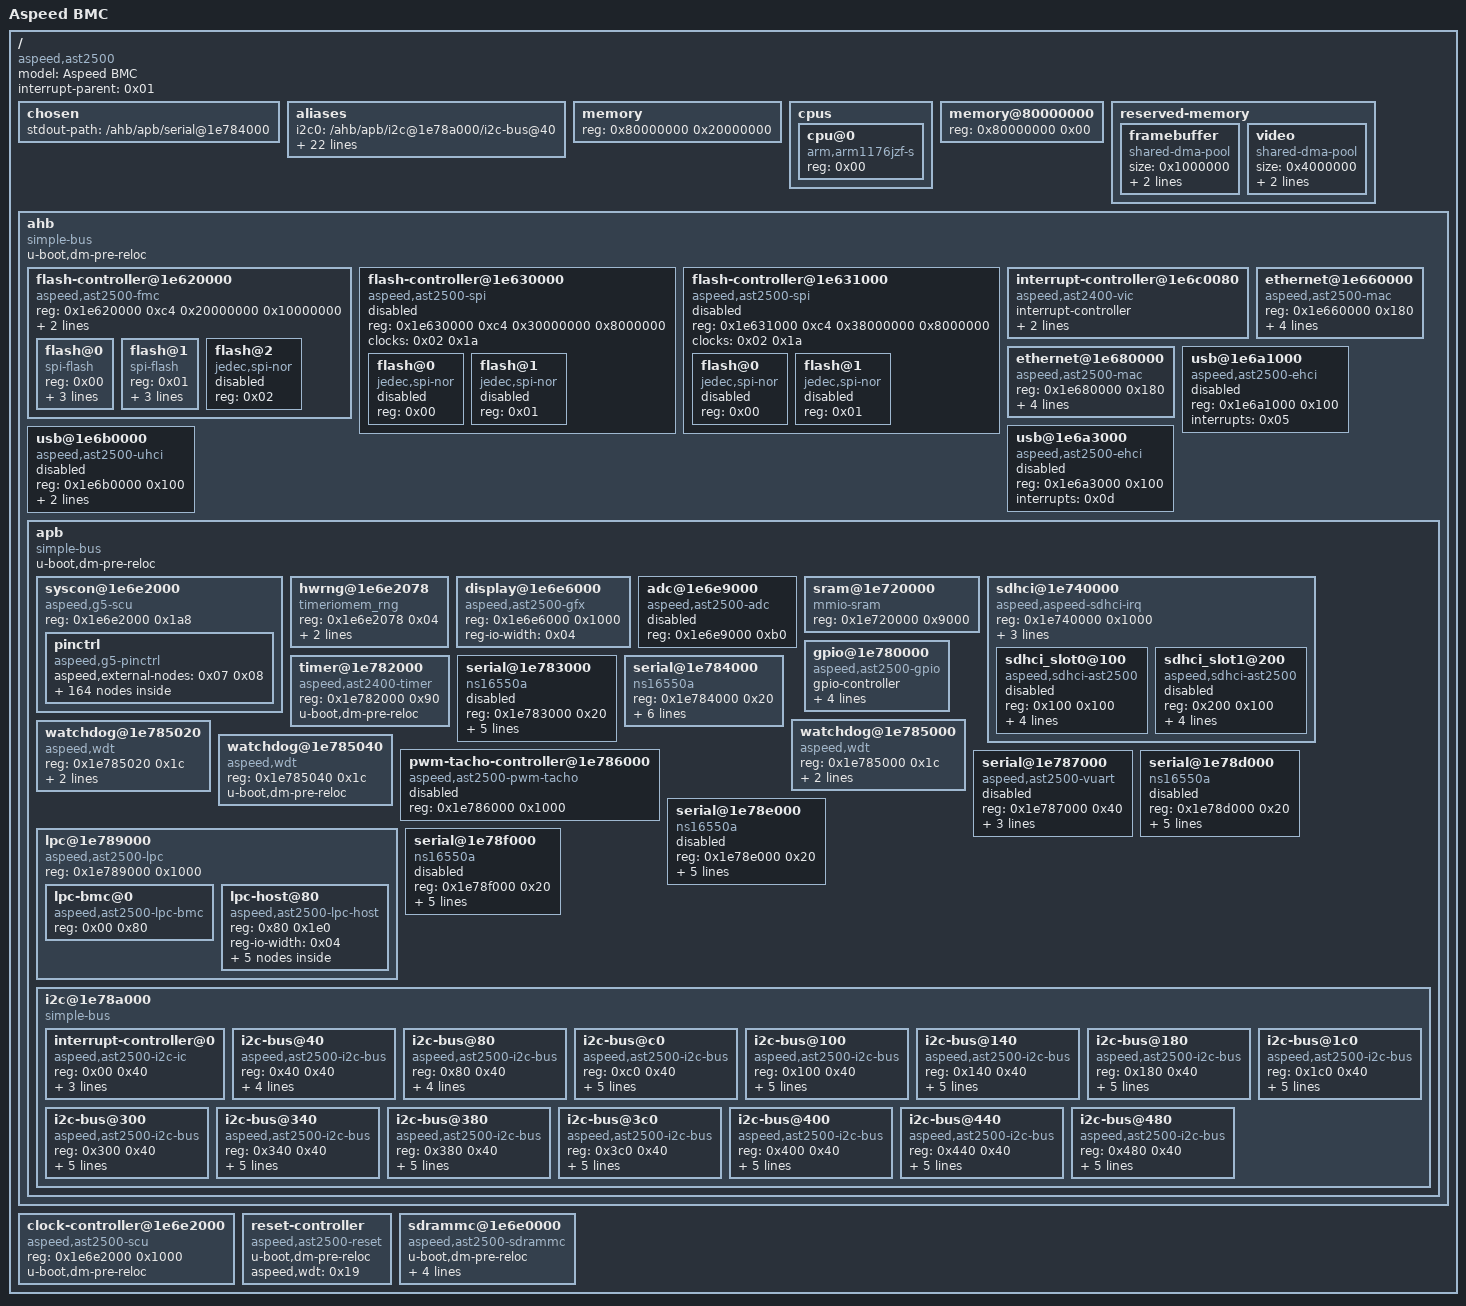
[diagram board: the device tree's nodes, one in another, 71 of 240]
/dts-v1/;

/ {
	#address-cells = <0x01>;
	#size-cells = <0x01>;
	model = "Aspeed BMC";
	compatible = "aspeed,ast2500";
	interrupt-parent = <0x01>;

	chosen {
		stdout-path = "/ahb/apb/serial@1e784000";
	};

	aliases {
		i2c0 = "/ahb/apb/i2c@1e78a000/i2c-bus@40";
		i2c1 = "/ahb/apb/i2c@1e78a000/i2c-bus@80";
		i2c2 = "/ahb/apb/i2c@1e78a000/i2c-bus@c0";
		i2c3 = "/ahb/apb/i2c@1e78a000/i2c-bus@100";
		i2c4 = "/ahb/apb/i2c@1e78a000/i2c-bus@140";
		i2c5 = "/ahb/apb/i2c@1e78a000/i2c-bus@180";
		i2c6 = "/ahb/apb/i2c@1e78a000/i2c-bus@1c0";
		i2c7 = "/ahb/apb/i2c@1e78a000/i2c-bus@300";
		i2c8 = "/ahb/apb/i2c@1e78a000/i2c-bus@340";
		i2c9 = "/ahb/apb/i2c@1e78a000/i2c-bus@380";
		i2c10 = "/ahb/apb/i2c@1e78a000/i2c-bus@3c0";
		i2c11 = "/ahb/apb/i2c@1e78a000/i2c-bus@400";
		i2c12 = "/ahb/apb/i2c@1e78a000/i2c-bus@440";
		i2c13 = "/ahb/apb/i2c@1e78a000/i2c-bus@480";
		serial0 = "/ahb/apb/serial@1e783000";
		serial1 = "/ahb/apb/serial@1e78d000";
		serial2 = "/ahb/apb/serial@1e78e000";
		serial3 = "/ahb/apb/serial@1e78f000";
		serial4 = "/ahb/apb/serial@1e784000";
		serial5 = "/ahb/apb/serial@1e787000";
		spi0 = "/ahb/flash-controller@1e620000";
		ethernet0 = "/ahb/ethernet@1e660000";
		ethernet1 = "/ahb/ethernet@1e680000";
	};

	memory {
		device_type = "memory";
		reg = <0x80000000 0x20000000>;
	};

	cpus {
		#address-cells = <0x01>;
		#size-cells = <0x00>;

		cpu@0 {
			compatible = "arm,arm1176jzf-s";
			device_type = "cpu";
			reg = <0x00>;
		};
	};

	memory@80000000 {
		device_type = "memory";
		reg = <0x80000000 0x00>;
	};

	reserved-memory {
		#address-cells = <0x01>;
		#size-cells = <0x01>;
		ranges;

		framebuffer {
			size = <0x1000000>;
			alignment = <0x1000000>;
			compatible = "shared-dma-pool";
			reusable;
		};

		video {
			size = <0x4000000>;
			alignment = <0x1000000>;
			compatible = "shared-dma-pool";
			no-map;
		};
	};

	ahb {
		compatible = "simple-bus";
		#address-cells = <0x01>;
		#size-cells = <0x01>;
		ranges;
		u-boot,dm-pre-reloc;

		flash-controller@1e620000 {
			reg = <0x1e620000 0xc4 0x20000000 0x10000000>;
			#address-cells = <0x01>;
			#size-cells = <0x00>;
			compatible = "aspeed,ast2500-fmc";
			status = "okay";
			interrupts = <0x13>;
			clocks = <0x02 0x1a>;

			flash@0 {
				reg = <0x00>;
				compatible = "spi-flash", "sst,w25q256";
				status = "okay";
				spi-max-frequency = <0x2faf080>;
				spi-tx-bus-width = <0x02>;
				spi-rx-bus-width = <0x02>;
			};

			flash@1 {
				reg = <0x01>;
				compatible = "spi-flash", "sst,w25q256";
				status = "okay";
				spi-max-frequency = <0x2faf080>;
				spi-tx-bus-width = <0x02>;
				spi-rx-bus-width = <0x02>;
			};

			flash@2 {
				reg = <0x02>;
				compatible = "jedec,spi-nor";
				status = "disabled";
			};
		};

		flash-controller@1e630000 {
			reg = <0x1e630000 0xc4 0x30000000 0x8000000>;
			#address-cells = <0x01>;
			#size-cells = <0x00>;
			compatible = "aspeed,ast2500-spi";
			clocks = <0x02 0x1a>;
			status = "disabled";

			flash@0 {
				reg = <0x00>;
				compatible = "jedec,spi-nor";
				status = "disabled";
			};

			flash@1 {
				reg = <0x01>;
				compatible = "jedec,spi-nor";
				status = "disabled";
			};
		};

		flash-controller@1e631000 {
			reg = <0x1e631000 0xc4 0x38000000 0x8000000>;
			#address-cells = <0x01>;
			#size-cells = <0x00>;
			compatible = "aspeed,ast2500-spi";
			clocks = <0x02 0x1a>;
			status = "disabled";

			flash@0 {
				reg = <0x00>;
				compatible = "jedec,spi-nor";
				status = "disabled";
			};

			flash@1 {
				reg = <0x01>;
				compatible = "jedec,spi-nor";
				status = "disabled";
			};
		};

		interrupt-controller@1e6c0080 {
			compatible = "aspeed,ast2400-vic";
			interrupt-controller;
			#interrupt-cells = <0x01>;
			valid-sources = <0xfefff7ff 0x807ffff>;
			reg = <0x1e6c0080 0x80>;
			phandle = <0x01>;
		};

		ethernet@1e660000 {
			compatible = "aspeed,ast2500-mac", "faraday,ftgmac100";
			reg = <0x1e660000 0x180>;
			interrupts = <0x02>;
			clocks = <0x02 0x11 0x02 0x26>;
			status = "okay";
			phy-mode = "rgmii";
			pinctrl-names = "default";
			pinctrl-0 = <0x03 0x04>;
		};

		ethernet@1e680000 {
			compatible = "aspeed,ast2500-mac", "faraday,ftgmac100";
			reg = <0x1e680000 0x180>;
			interrupts = <0x03>;
			clocks = <0x02 0x12 0x02 0x26>;
			status = "okay";
			phy-mode = "rgmii";
			pinctrl-names = "default";
			pinctrl-0 = <0x05 0x06>;
		};

		usb@1e6a1000 {
			compatible = "aspeed,ast2500-ehci", "generic-ehci";
			reg = <0x1e6a1000 0x100>;
			interrupts = <0x05>;
			status = "disabled";
		};

		usb@1e6a3000 {
			compatible = "aspeed,ast2500-ehci", "generic-ehci";
			reg = <0x1e6a3000 0x100>;
			interrupts = <0x0d>;
			status = "disabled";
		};

		usb@1e6b0000 {
			compatible = "aspeed,ast2500-uhci", "generic-uhci";
			reg = <0x1e6b0000 0x100>;
			interrupts = <0x0e>;
			#ports = <0x02>;
			status = "disabled";
		};

		apb {
			compatible = "simple-bus";
			#address-cells = <0x01>;
			#size-cells = <0x01>;
			ranges;
			u-boot,dm-pre-reloc;

			syscon@1e6e2000 {
				compatible = "aspeed,g5-scu", "syscon", "simple-mfd";
				reg = <0x1e6e2000 0x1a8>;
				#clock-cells = <0x01>;
				#reset-cells = <0x01>;

				pinctrl {
					compatible = "aspeed,g5-pinctrl";
					aspeed,external-nodes = <0x07 0x08>;
					phandle = <0x0a>;

					acpi_default {
						function = "ACPI";
						groups = "ACPI";
					};

					adc0_default {
						function = "ADC0";
						groups = "ADC0";
					};

					adc1_default {
						function = "ADC1";
						groups = "ADC1";
					};

					adc10_default {
						function = "ADC10";
						groups = "ADC10";
					};

					adc11_default {
						function = "ADC11";
						groups = "ADC11";
					};

					adc12_default {
						function = "ADC12";
						groups = "ADC12";
					};

					adc13_default {
						function = "ADC13";
						groups = "ADC13";
					};

					adc14_default {
						function = "ADC14";
						groups = "ADC14";
					};

					adc15_default {
						function = "ADC15";
						groups = "ADC15";
					};

					adc2_default {
						function = "ADC2";
						groups = "ADC2";
					};

					adc3_default {
						function = "ADC3";
						groups = "ADC3";
					};

					adc4_default {
						function = "ADC4";
						groups = "ADC4";
					};

					adc5_default {
						function = "ADC5";
						groups = "ADC5";
					};

					adc6_default {
						function = "ADC6";
						groups = "ADC6";
					};

					adc7_default {
						function = "ADC7";
						groups = "ADC7";
					};

					adc8_default {
						function = "ADC8";
						groups = "ADC8";
					};

					adc9_default {
						function = "ADC9";
						groups = "ADC9";
					};

					bmcint_default {
						function = "BMCINT";
						groups = "BMCINT";
					};

					ddcclk_default {
						function = "DDCCLK";
						groups = "DDCCLK";
					};

					ddcdat_default {
						function = "DDCDAT";
						groups = "DDCDAT";
					};

					espi_default {
						function = "ESPI";
						groups = "ESPI";
					};

					fwspics1_default {
						function = "FWSPICS1";
						groups = "FWSPICS1";
					};

					fwspics2_default {
						function = "FWSPICS2";
						groups = "FWSPICS2";
					};

					gpid0_default {
						function = "GPID0";
						groups = "GPID0";
					};

					gpid2_default {
						function = "GPID2";
						groups = "GPID2";
					};

					gpid4_default {
						function = "GPID4";
						groups = "GPID4";
					};

					gpid6_default {
						function = "GPID6";
						groups = "GPID6";
					};

					gpie0_default {
						function = "GPIE0";
						groups = "GPIE0";
					};

					gpie2_default {
						function = "GPIE2";
						groups = "GPIE2";
					};

					gpie4_default {
						function = "GPIE4";
						groups = "GPIE4";
					};

					gpie6_default {
						function = "GPIE6";
						groups = "GPIE6";
					};

					i2c10_default {
						function = "I2C10";
						groups = "I2C10";
						phandle = <0x14>;
					};

					i2c11_default {
						function = "I2C11";
						groups = "I2C11";
						phandle = <0x15>;
					};

					i2c12_default {
						function = "I2C12";
						groups = "I2C12";
						phandle = <0x16>;
					};

					i2c13_default {
						function = "I2C13";
						groups = "I2C13";
						phandle = <0x17>;
					};

					i2c14_default {
						function = "I2C14";
						groups = "I2C14";
						phandle = <0x18>;
					};

					i2c3_default {
						function = "I2C3";
						groups = "I2C3";
						phandle = <0x0d>;
					};

					i2c4_default {
						function = "I2C4";
						groups = "I2C4";
						phandle = <0x0e>;
					};

					i2c5_default {
						function = "I2C5";
						groups = "I2C5";
						phandle = <0x0f>;
					};

					i2c6_default {
						function = "I2C6";
						groups = "I2C6";
						phandle = <0x10>;
					};

					i2c7_default {
						function = "I2C7";
						groups = "I2C7";
						phandle = <0x11>;
					};

					i2c8_default {
						function = "I2C8";
						groups = "I2C8";
						phandle = <0x12>;
					};

					i2c9_default {
						function = "I2C9";
						groups = "I2C9";
						phandle = <0x13>;
					};

					lad0_default {
						function = "LAD0";
						groups = "LAD0";
					};

					lad1_default {
						function = "LAD1";
						groups = "LAD1";
					};

					lad2_default {
						function = "LAD2";
						groups = "LAD2";
					};

					lad3_default {
						function = "LAD3";
						groups = "LAD3";
					};

					lclk_default {
						function = "LCLK";
						groups = "LCLK";
					};

					lframe_default {
						function = "LFRAME";
						groups = "LFRAME";
					};

					lpchc_default {
						function = "LPCHC";
						groups = "LPCHC";
					};

					lpcpd_default {
						function = "LPCPD";
						groups = "LPCPD";
					};

					lpcplus_default {
						function = "LPCPLUS";
						groups = "LPCPLUS";
					};

					lpcpme_default {
						function = "LPCPME";
						groups = "LPCPME";
					};

					lpcrst_default {
						function = "LPCRST";
						groups = "LPCRST";
					};

					lpcsmi_default {
						function = "LPCSMI";
						groups = "LPCSMI";
					};

					lsirq_default {
						function = "LSIRQ";
						groups = "LSIRQ";
					};

					mac1link_default {
						function = "MAC1LINK";
						groups = "MAC1LINK";
						phandle = <0x03>;
					};

					mac2link_default {
						function = "MAC2LINK";
						groups = "MAC2LINK";
						phandle = <0x05>;
					};

					mdio1_default {
						function = "MDIO1";
						groups = "MDIO1";
						phandle = <0x04>;
					};

					mdio2_default {
						function = "MDIO2";
						groups = "MDIO2";
						phandle = <0x06>;
					};

					ncts1_default {
						function = "NCTS1";
						groups = "NCTS1";
					};

					ncts2_default {
						function = "NCTS2";
						groups = "NCTS2";
					};

					ncts3_default {
						function = "NCTS3";
						groups = "NCTS3";
					};

					ncts4_default {
						function = "NCTS4";
						groups = "NCTS4";
					};

					ndcd1_default {
						function = "NDCD1";
						groups = "NDCD1";
					};

					ndcd2_default {
						function = "NDCD2";
						groups = "NDCD2";
					};

					ndcd3_default {
						function = "NDCD3";
						groups = "NDCD3";
					};

					ndcd4_default {
						function = "NDCD4";
						groups = "NDCD4";
					};

					ndsr1_default {
						function = "NDSR1";
						groups = "NDSR1";
					};

					ndsr2_default {
						function = "NDSR2";
						groups = "NDSR2";
					};

					ndsr3_default {
						function = "NDSR3";
						groups = "NDSR3";
					};

					ndsr4_default {
						function = "NDSR4";
						groups = "NDSR4";
					};

					ndtr1_default {
						function = "NDTR1";
						groups = "NDTR1";
					};

					ndtr2_default {
						function = "NDTR2";
						groups = "NDTR2";
					};

					ndtr3_default {
						function = "NDTR3";
						groups = "NDTR3";
					};

					ndtr4_default {
						function = "NDTR4";
						groups = "NDTR4";
					};

					nri1_default {
						function = "NRI1";
						groups = "NRI1";
					};

					nri2_default {
						function = "NRI2";
						groups = "NRI2";
					};

					nri3_default {
						function = "NRI3";
						groups = "NRI3";
					};

					nri4_default {
						function = "NRI4";
						groups = "NRI4";
					};

					nrts1_default {
						function = "NRTS1";
						groups = "NRTS1";
					};

					nrts2_default {
						function = "NRTS2";
						groups = "NRTS2";
					};

					nrts3_default {
						function = "NRTS3";
						groups = "NRTS3";
					};

					nrts4_default {
						function = "NRTS4";
						groups = "NRTS4";
					};

					oscclk_default {
						function = "OSCCLK";
						groups = "OSCCLK";
					};

					pewake_default {
						function = "PEWAKE";
						groups = "PEWAKE";
					};

					pnor_default {
						function = "PNOR";
						groups = "PNOR";
					};

					pwm0_default {
						function = "PWM0";
						groups = "PWM0";
					};

					pwm1_default {
						function = "PWM1";
						groups = "PWM1";
					};

					pwm2_default {
						function = "PWM2";
						groups = "PWM2";
					};

					pwm3_default {
						function = "PWM3";
						groups = "PWM3";
					};

					pwm4_default {
						function = "PWM4";
						groups = "PWM4";
					};

					pwm5_default {
						function = "PWM5";
						groups = "PWM5";
					};

					pwm6_default {
						function = "PWM6";
						groups = "PWM6";
					};

					pwm7_default {
						function = "PWM7";
						groups = "PWM7";
					};

					rgmii1_default {
						function = "RGMII1";
						groups = "RGMII1";
					};

					rgmii2_default {
						function = "RGMII2";
						groups = "RGMII2";
					};

					rmii1_default {
						function = "RMII1";
						groups = "RMII1";
					};

					rmii2_default {
						function = "RMII2";
						groups = "RMII2";
					};

					rxd1_default {
						function = "RXD1";
						groups = "RXD1";
					};

					rxd2_default {
						function = "RXD2";
						groups = "RXD2";
					};

					rxd3_default {
						function = "RXD3";
						groups = "RXD3";
					};

					rxd4_default {
						function = "RXD4";
						groups = "RXD4";
					};

					salt1_default {
						function = "SALT1";
						groups = "SALT1";
					};

					salt10_default {
						function = "SALT10";
						groups = "SALT10";
					};

					salt11_default {
						function = "SALT11";
						groups = "SALT11";
					};

					salt12_default {
						function = "SALT12";
						groups = "SALT12";
					};

					salt13_default {
						function = "SALT13";
						groups = "SALT13";
					};

					salt14_default {
						function = "SALT14";
						groups = "SALT14";
					};

					salt2_default {
						function = "SALT2";
						groups = "SALT2";
					};

					salt3_default {
						function = "SALT3";
						groups = "SALT3";
					};

					salt4_default {
						function = "SALT4";
						groups = "SALT4";
					};

					salt5_default {
						function = "SALT5";
						groups = "SALT5";
					};

					salt6_default {
						function = "SALT6";
						groups = "SALT6";
					};

					salt7_default {
						function = "SALT7";
						groups = "SALT7";
					};

					salt8_default {
						function = "SALT8";
						groups = "SALT8";
					};

					salt9_default {
						function = "SALT9";
						groups = "SALT9";
					};

					scl1_default {
						function = "SCL1";
						groups = "SCL1";
					};

					scl2_default {
						function = "SCL2";
						groups = "SCL2";
					};

					sd1_default {
						function = "SD1";
						groups = "SD1";
					};

					sd2_default {
						function = "SD2";
						groups = "SD2";
					};

					sda1_default {
						function = "SDA1";
						groups = "SDA1";
					};

					sda2_default {
						function = "SDA2";
						groups = "SDA2";
					};

					sgps1_default {
						function = "SGPS1";
						groups = "SGPS1";
					};

					sgps2_default {
						function = "SGPS2";
						groups = "SGPS2";
					};

					sioonctrl_default {
						function = "SIOONCTRL";
						groups = "SIOONCTRL";
					};

					siopbi_default {
						function = "SIOPBI";
						groups = "SIOPBI";
					};

					siopbo_default {
						function = "SIOPBO";
						groups = "SIOPBO";
					};

					siopwreq_default {
						function = "SIOPWREQ";
						groups = "SIOPWREQ";
					};

					siopwrgd_default {
						function = "SIOPWRGD";
						groups = "SIOPWRGD";
					};

					sios3_default {
						function = "SIOS3";
						groups = "SIOS3";
					};

					sios5_default {
						function = "SIOS5";
						groups = "SIOS5";
					};

					siosci_default {
						function = "SIOSCI";
						groups = "SIOSCI";
					};

					spi1_default {
						function = "SPI1";
						groups = "SPI1";
					};

					spi1cs1_default {
						function = "SPI1CS1";
						groups = "SPI1CS1";
					};

					spi1debug_default {
						function = "SPI1DEBUG";
						groups = "SPI1DEBUG";
					};

					spi1passthru_default {
						function = "SPI1PASSTHRU";
						groups = "SPI1PASSTHRU";
					};

					spi2ck_default {
						function = "SPI2CK";
						groups = "SPI2CK";
					};

					spi2cs0_default {
						function = "SPI2CS0";
						groups = "SPI2CS0";
					};

					spi2cs1_default {
						function = "SPI2CS1";
						groups = "SPI2CS1";
					};

					spi2miso_default {
						function = "SPI2MISO";
						groups = "SPI2MISO";
					};

					spi2mosi_default {
						function = "SPI2MOSI";
						groups = "SPI2MOSI";
					};

					timer3_default {
						function = "TIMER3";
						groups = "TIMER3";
					};

					timer4_default {
						function = "TIMER4";
						groups = "TIMER4";
					};

					timer5_default {
						function = "TIMER5";
						groups = "TIMER5";
					};

					timer6_default {
						function = "TIMER6";
						groups = "TIMER6";
					};

					timer7_default {
						function = "TIMER7";
						groups = "TIMER7";
					};

					timer8_default {
						function = "TIMER8";
						groups = "TIMER8";
					};

					txd1_default {
						function = "TXD1";
						groups = "TXD1";
					};

					txd2_default {
						function = "TXD2";
						groups = "TXD2";
					};

					txd3_default {
						function = "TXD3";
						groups = "TXD3";
					};

					txd4_default {
						function = "TXD4";
						groups = "TXD4";
					};

					uart6_default {
						function = "UART6";
						groups = "UART6";
					};

					usbcki_default {
						function = "USBCKI";
						groups = "USBCKI";
					};

					usb2ah_default {
						function = "USB2AH";
						groups = "USB2AH";
					};

					usb11bhid_default {
						function = "USB11BHID";
						groups = "USB11BHID";
					};

					usb2bh_default {
						function = "USB2BH";
						groups = "USB2BH";
					};

					vgabiosrom_default {
						function = "VGABIOSROM";
						groups = "VGABIOSROM";
					};

					vgahs_default {
						function = "VGAHS";
						groups = "VGAHS";
					};

					vgavs_default {
						function = "VGAVS";
						groups = "VGAVS";
					};

					vpi24_default {
						function = "VPI24";
						groups = "VPI24";
					};

					vpo_default {
						function = "VPO";
						groups = "VPO";
					};

					wdtrst1_default {
						function = "WDTRST1";
						groups = "WDTRST1";
					};

					wdtrst2_default {
						function = "WDTRST2";
						groups = "WDTRST2";
					};
				};
			};

			hwrng@1e6e2078 {
				compatible = "timeriomem_rng";
				reg = <0x1e6e2078 0x04>;
				period = <0x01>;
				quality = <0x64>;
			};

			display@1e6e6000 {
				compatible = "aspeed,ast2500-gfx", "syscon";
				reg = <0x1e6e6000 0x1000>;
				reg-io-width = <0x04>;
				phandle = <0x07>;
			};

			adc@1e6e9000 {
				compatible = "aspeed,ast2500-adc";
				reg = <0x1e6e9000 0xb0>;
				#io-channel-cells = <0x01>;
				status = "disabled";
			};

			sram@1e720000 {
				compatible = "mmio-sram";
				reg = <0x1e720000 0x9000>;
			};

			sdhci@1e740000 {
				#interrupt-cells = <0x01>;
				compatible = "aspeed,aspeed-sdhci-irq", "simple-mfd";
				reg = <0x1e740000 0x1000>;
				interrupts = <0x1a>;
				interrupt-controller;
				clocks = <0x02 0x16 0x02 0x18>;
				clock-names = "ctrlclk", "extclk";
				#address-cells = <0x01>;
				#size-cells = <0x01>;
				ranges = <0x00 0x1e740000 0x1000>;
				phandle = <0x09>;

				sdhci_slot0@100 {
					compatible = "aspeed,sdhci-ast2500";
					reg = <0x100 0x100>;
					interrupts = <0x00>;
					interrupt-parent = <0x09>;
					sdhci,auto-cmd12;
					clocks = <0x02 0x1d>;
					status = "disabled";
				};

				sdhci_slot1@200 {
					compatible = "aspeed,sdhci-ast2500";
					reg = <0x200 0x100>;
					interrupts = <0x01>;
					interrupt-parent = <0x09>;
					sdhci,auto-cmd12;
					clocks = <0x02 0x1d>;
					status = "disabled";
				};
			};

			gpio@1e780000 {
				#gpio-cells = <0x02>;
				gpio-controller;
				compatible = "aspeed,ast2500-gpio";
				reg = <0x1e780000 0x1000>;
				interrupts = <0x14>;
				gpio-ranges = <0x0a 0x00 0x00 0xdc>;
				interrupt-controller;
			};

			timer@1e782000 {
				compatible = "aspeed,ast2400-timer";
				reg = <0x1e782000 0x90>;
				u-boot,dm-pre-reloc;
			};

			serial@1e783000 {
				compatible = "ns16550a";
				reg = <0x1e783000 0x20>;
				reg-shift = <0x02>;
				interrupts = <0x09>;
				clocks = <0x02 0x0d>;
				clock-frequency = <0x16e3600>;
				no-loopback-test;
				status = "disabled";
			};

			serial@1e784000 {
				compatible = "ns16550a";
				reg = <0x1e784000 0x20>;
				reg-shift = <0x02>;
				interrupts = <0x0a>;
				clocks = <0x02 0x0f>;
				clock-frequency = <0x16e3600>;
				no-loopback-test;
				status = "okay";
				u-boot,dm-pre-reloc;
			};

			watchdog@1e785000 {
				compatible = "aspeed,wdt";
				reg = <0x1e785000 0x1c>;
				interrupts = <0x1b>;
				u-boot,dm-pre-reloc;
				status = "okay";
				phandle = <0x19>;
			};

			watchdog@1e785020 {
				compatible = "aspeed,wdt";
				reg = <0x1e785020 0x1c>;
				interrupts = <0x1b>;
				status = "okay";
				u-boot,dm-pre-reloc;
			};

			watchdog@1e785040 {
				compatible = "aspeed,wdt";
				reg = <0x1e785040 0x1c>;
				status = "okay";
				u-boot,dm-pre-reloc;
			};

			pwm-tacho-controller@1e786000 {
				compatible = "aspeed,ast2500-pwm-tacho";
				#address-cells = <0x01>;
				#size-cells = <0x00>;
				reg = <0x1e786000 0x1000>;
				status = "disabled";
			};

			serial@1e787000 {
				compatible = "aspeed,ast2500-vuart";
				reg = <0x1e787000 0x40>;
				reg-shift = <0x02>;
				interrupts = <0x08>;
				no-loopback-test;
				status = "disabled";
			};

			lpc@1e789000 {
				compatible = "aspeed,ast2500-lpc", "simple-mfd";
				reg = <0x1e789000 0x1000>;
				#address-cells = <0x01>;
				#size-cells = <0x01>;
				ranges = <0x00 0x1e789000 0x1000>;

				lpc-bmc@0 {
					compatible = "aspeed,ast2500-lpc-bmc";
					reg = <0x00 0x80>;
				};

				lpc-host@80 {
					compatible = "aspeed,ast2500-lpc-host", "simple-mfd", "syscon";
					reg = <0x80 0x1e0>;
					reg-io-width = <0x04>;
					#address-cells = <0x01>;
					#size-cells = <0x01>;
					ranges = <0x00 0x80 0x1e0>;

					lpc-ctrl@0 {
						compatible = "aspeed,ast2500-lpc-ctrl";
						reg = <0x00 0x80>;
						status = "disabled";
					};

					lpc-snoop@0 {
						compatible = "aspeed,ast2500-lpc-snoop";
						reg = <0x00 0x80>;
						interrupts = <0x08>;
						status = "disabled";
					};

					lhc@20 {
						compatible = "aspeed,ast2500-lhc";
						reg = <0x20 0x24 0x48 0x08>;
						phandle = <0x08>;
					};

					reset-controller@18 {
						compatible = "aspeed,ast2500-lpc-reset";
						reg = <0x18 0x04>;
						#reset-cells = <0x01>;
					};

					ibt@c0 {
						compatible = "aspeed,ast2500-ibt-bmc";
						reg = <0xc0 0x18>;
						interrupts = <0x08>;
						status = "disabled";
					};
				};
			};

			serial@1e78d000 {
				compatible = "ns16550a";
				reg = <0x1e78d000 0x20>;
				reg-shift = <0x02>;
				interrupts = <0x20>;
				clocks = <0x02 0x0e>;
				clock-frequency = <0x16e3600>;
				no-loopback-test;
				status = "disabled";
			};

			serial@1e78e000 {
				compatible = "ns16550a";
				reg = <0x1e78e000 0x20>;
				reg-shift = <0x02>;
				interrupts = <0x21>;
				clocks = <0x02 0x14>;
				clock-frequency = <0x16e3600>;
				no-loopback-test;
				status = "disabled";
			};

			serial@1e78f000 {
				compatible = "ns16550a";
				reg = <0x1e78f000 0x20>;
				reg-shift = <0x02>;
				interrupts = <0x22>;
				clocks = <0x02 0x15>;
				clock-frequency = <0x16e3600>;
				no-loopback-test;
				status = "disabled";
			};

			i2c@1e78a000 {
				compatible = "simple-bus";
				#address-cells = <0x01>;
				#size-cells = <0x01>;
				ranges = <0x00 0x1e78a000 0x1000>;

				interrupt-controller@0 {
					#interrupt-cells = <0x01>;
					compatible = "aspeed,ast2500-i2c-ic";
					reg = <0x00 0x40>;
					interrupts = <0x0c>;
					interrupt-controller;
					resets = <0x0b 0x02>;
					phandle = <0x0c>;
				};

				i2c-bus@40 {
					#address-cells = <0x01>;
					#size-cells = <0x00>;
					#interrupt-cells = <0x01>;
					reg = <0x40 0x40>;
					compatible = "aspeed,ast2500-i2c-bus";
					bus-frequency = <0x186a0>;
					interrupts = <0x00>;
					interrupt-parent = <0x0c>;
					clocks = <0x02 0x1b>;
					status = "okay";
				};

				i2c-bus@80 {
					#address-cells = <0x01>;
					#size-cells = <0x00>;
					#interrupt-cells = <0x01>;
					reg = <0x80 0x40>;
					compatible = "aspeed,ast2500-i2c-bus";
					bus-frequency = <0x186a0>;
					interrupts = <0x01>;
					interrupt-parent = <0x0c>;
					clocks = <0x02 0x1b>;
					status = "okay";
				};

				i2c-bus@c0 {
					#address-cells = <0x01>;
					#size-cells = <0x00>;
					#interrupt-cells = <0x01>;
					reg = <0xc0 0x40>;
					compatible = "aspeed,ast2500-i2c-bus";
					bus-frequency = <0x186a0>;
					interrupts = <0x02>;
					interrupt-parent = <0x0c>;
					clocks = <0x02 0x1b>;
					pinctrl-names = "default";
					pinctrl-0 = <0x0d>;
					status = "okay";
				};

				i2c-bus@100 {
					#address-cells = <0x01>;
					#size-cells = <0x00>;
					#interrupt-cells = <0x01>;
					reg = <0x100 0x40>;
					compatible = "aspeed,ast2500-i2c-bus";
					bus-frequency = <0x186a0>;
					interrupts = <0x03>;
					interrupt-parent = <0x0c>;
					clocks = <0x02 0x1b>;
					pinctrl-names = "default";
					pinctrl-0 = <0x0e>;
					status = "okay";
				};

				i2c-bus@140 {
					#address-cells = <0x01>;
					#size-cells = <0x00>;
					#interrupt-cells = <0x01>;
					reg = <0x140 0x40>;
					compatible = "aspeed,ast2500-i2c-bus";
					bus-frequency = <0x186a0>;
					interrupts = <0x04>;
					interrupt-parent = <0x0c>;
					clocks = <0x02 0x1b>;
					pinctrl-names = "default";
					pinctrl-0 = <0x0f>;
					status = "okay";
				};

				i2c-bus@180 {
					#address-cells = <0x01>;
					#size-cells = <0x00>;
					#interrupt-cells = <0x01>;
					reg = <0x180 0x40>;
					compatible = "aspeed,ast2500-i2c-bus";
					bus-frequency = <0x186a0>;
					interrupts = <0x05>;
					interrupt-parent = <0x0c>;
					clocks = <0x02 0x1b>;
					pinctrl-names = "default";
					pinctrl-0 = <0x10>;
					status = "okay";
				};

				i2c-bus@1c0 {
					#address-cells = <0x01>;
					#size-cells = <0x00>;
					#interrupt-cells = <0x01>;
					reg = <0x1c0 0x40>;
					compatible = "aspeed,ast2500-i2c-bus";
					bus-frequency = <0x186a0>;
					interrupts = <0x06>;
					interrupt-parent = <0x0c>;
					clocks = <0x02 0x1b>;
					pinctrl-names = "default";
					pinctrl-0 = <0x11>;
					status = "okay";
				};

				i2c-bus@300 {
					#address-cells = <0x01>;
					#size-cells = <0x00>;
					#interrupt-cells = <0x01>;
					reg = <0x300 0x40>;
					compatible = "aspeed,ast2500-i2c-bus";
					bus-frequency = <0x186a0>;
					interrupts = <0x07>;
					interrupt-parent = <0x0c>;
					clocks = <0x02 0x1b>;
					pinctrl-names = "default";
					pinctrl-0 = <0x12>;
					status = "okay";
				};

				i2c-bus@340 {
					#address-cells = <0x01>;
					#size-cells = <0x00>;
					#interrupt-cells = <0x01>;
					reg = <0x340 0x40>;
					compatible = "aspeed,ast2500-i2c-bus";
					bus-frequency = <0x186a0>;
					interrupts = <0x08>;
					interrupt-parent = <0x0c>;
					clocks = <0x02 0x1b>;
					pinctrl-names = "default";
					pinctrl-0 = <0x13>;
					status = "okay";
				};

				i2c-bus@380 {
					#address-cells = <0x01>;
					#size-cells = <0x00>;
					#interrupt-cells = <0x01>;
					reg = <0x380 0x40>;
					compatible = "aspeed,ast2500-i2c-bus";
					bus-frequency = <0x186a0>;
					interrupts = <0x09>;
					interrupt-parent = <0x0c>;
					clocks = <0x02 0x1b>;
					pinctrl-names = "default";
					pinctrl-0 = <0x14>;
					status = "okay";
				};

				i2c-bus@3c0 {
					#address-cells = <0x01>;
					#size-cells = <0x00>;
					#interrupt-cells = <0x01>;
					reg = <0x3c0 0x40>;
					compatible = "aspeed,ast2500-i2c-bus";
					bus-frequency = <0x186a0>;
					interrupts = <0x0a>;
					interrupt-parent = <0x0c>;
					clocks = <0x02 0x1b>;
					pinctrl-names = "default";
					pinctrl-0 = <0x15>;
					status = "okay";
				};

				i2c-bus@400 {
					#address-cells = <0x01>;
					#size-cells = <0x00>;
					#interrupt-cells = <0x01>;
					reg = <0x400 0x40>;
					compatible = "aspeed,ast2500-i2c-bus";
					bus-frequency = <0x186a0>;
					interrupts = <0x0b>;
					interrupt-parent = <0x0c>;
					clocks = <0x02 0x1b>;
					pinctrl-names = "default";
					pinctrl-0 = <0x16>;
					status = "okay";
				};

				i2c-bus@440 {
					#address-cells = <0x01>;
					#size-cells = <0x00>;
					#interrupt-cells = <0x01>;
					reg = <0x440 0x40>;
					compatible = "aspeed,ast2500-i2c-bus";
					bus-frequency = <0x186a0>;
					interrupts = <0x0c>;
					interrupt-parent = <0x0c>;
					clocks = <0x02 0x1b>;
					pinctrl-names = "default";
					pinctrl-0 = <0x17>;
					status = "okay";
				};

				i2c-bus@480 {
					#address-cells = <0x01>;
					#size-cells = <0x00>;
					#interrupt-cells = <0x01>;
					reg = <0x480 0x40>;
					compatible = "aspeed,ast2500-i2c-bus";
					bus-frequency = <0x186a0>;
					interrupts = <0x0d>;
					interrupt-parent = <0x0c>;
					clocks = <0x02 0x1b>;
					pinctrl-names = "default";
					pinctrl-0 = <0x18>;
					status = "okay";
				};
			};
		};
	};

	clock-controller@1e6e2000 {
		compatible = "aspeed,ast2500-scu";
		reg = <0x1e6e2000 0x1000>;
		u-boot,dm-pre-reloc;
		#clock-cells = <0x01>;
		#reset-cells = <0x01>;
		phandle = <0x02>;
	};

	reset-controller {
		u-boot,dm-pre-reloc;
		compatible = "aspeed,ast2500-reset";
		aspeed,wdt = <0x19>;
		#reset-cells = <0x01>;
		phandle = <0x0b>;
	};

	sdrammc@1e6e0000 {
		u-boot,dm-pre-reloc;
		compatible = "aspeed,ast2500-sdrammc";
		reg = <0x1e6e0000 0x174 0x1e6e0200 0x1d4>;
		#reset-cells = <0x01>;
		clocks = <0x02 0x23>;
		resets = <0x0b 0x00>;
		clock-frequency = <0x17d78400>;
	};
};
